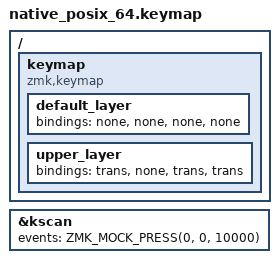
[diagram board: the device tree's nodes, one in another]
#include <behaviors.dtsi>
#include <dt-bindings/zmk/kscan_mock.h>

/ {
    keymap {
        compatible = "zmk,keymap";
        default_layer {
            bindings = <&none &none &none &none>;
        };
        upper_layer {
            bindings = <&trans &none &trans &trans>;
        };
    };
};

/* The probe exits before this synthetic event. */
&kscan {
    events = <ZMK_MOCK_PRESS(0, 0, 10000)>;
};
